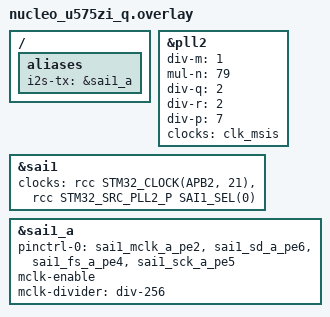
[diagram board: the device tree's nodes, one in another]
/*
 * Copyright (c) 2025 ZAL Zentrum für Angewandte Luftfahrtforschung GmbH
 * Copyright (c) 2025 Mario Paja
 *
 * SPDX-License-Identifier: Apache-2.0
 */

/ {
	aliases {
		i2s-tx = &sai1_a;
	};
};

&pll2 {
	/* 44.1KHz (-0.03% Error) */
	div-m = <1>;
	mul-n = <79>;
	div-q = <2>;
	div-r = <2>;
	div-p = <7>;
	clocks = <&clk_msis>;
	status = "okay";
};

&sai1 {
	clocks = <&rcc STM32_CLOCK(APB2, 21)>,
		 <&rcc STM32_SRC_PLL2_P SAI1_SEL(0)>;
	clock-names = "sai_ck", "sai_ker_ck";
	status = "okay";
};

&sai1_a {
	pinctrl-0 = <&sai1_mclk_a_pe2 &sai1_sd_a_pe6
		     &sai1_fs_a_pe4 &sai1_sck_a_pe5>;
	pinctrl-names = "default";
	mclk-enable;
	mclk-divider = "div-256";
	dma-names = "tx";
	status = "okay";
};
